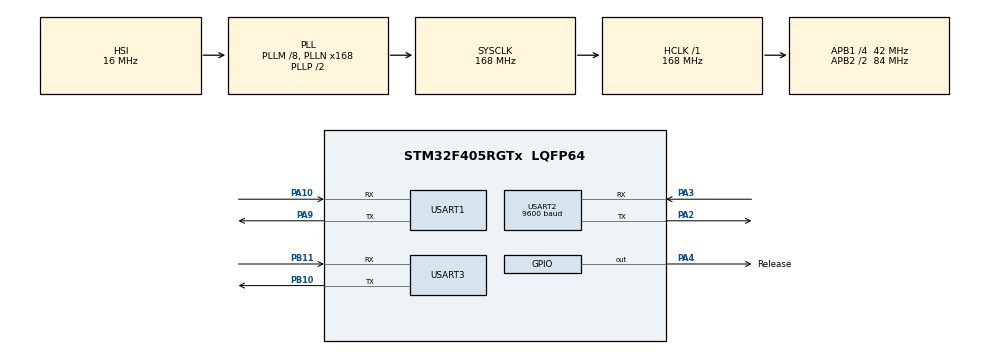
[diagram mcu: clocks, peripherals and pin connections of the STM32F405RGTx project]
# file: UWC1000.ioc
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FREERTOS.Tasks01=defaultTask,24,128,StartDefaultTask,Default,NULL,Dynamic,NULL,NULL;SensorTask,8,1024,StartSensorTask,Default,NULL,Dynamic,NULL,NULL;MavlinkTask,8,1024,StartMavlinkTask,Default,NULL,Dynamic,NULL,NULL;ReleaseTask,8,128,StartReleaseTask,Default,NULL,Dynamic,NULL,NULL
Mcu.Family=STM32F4
Mcu.Name=STM32F405RGTx
Mcu.Package=LQFP64
NVIC.PriorityGroup=NVIC_PRIORITYGROUP_4
NVIC.TIM6_DAC_IRQn=true\:15\:0\:false\:false\:true\:false\:false\:true\:true
NVIC.TimeBase=TIM6_DAC_IRQn
NVIC.TimeBaseIP=TIM6
NVIC.USART1_IRQn=true\:5\:0\:false\:false\:true\:true\:true\:true\:true
PA10.Mode=Asynchronous
PA10.Signal=USART1_RX
PA13.Mode=Serial_Wire
PA13.Signal=SYS_JTMS-SWDIO
PA14.Mode=Serial_Wire
PA14.Signal=SYS_JTCK-SWCLK
PA2.Mode=Asynchronous
PA2.Signal=USART2_TX
PA3.Mode=Asynchronous
PA3.Signal=USART2_RX
PA4.GPIO_Label=Release
PA4.Signal=GPIO_Output
PA9.Mode=Asynchronous
PA9.Signal=USART1_TX
PB10.Mode=Asynchronous
PB10.Signal=USART3_TX
PB11.Mode=Asynchronous
PB11.Signal=USART3_RX
PH0-OSC_IN.Mode=HSE-External-Clock-Source
PH0-OSC_IN.Signal=RCC_OSC_IN
PH1-OSC_OUT.Mode=HSE-External-Clock-Source
PH1-OSC_OUT.Signal=RCC_OSC_OUT
ProjectManager.HeapSize=0x200
ProjectManager.StackSize=0x400
ProjectManager.TargetToolchain=MDK-ARM V5.32
RCC.48MHZClocksFreq_Value=84000000
RCC.AHBFreq_Value=168000000
RCC.APB1CLKDivider=RCC_HCLK_DIV4
RCC.APB1Freq_Value=42000000
RCC.APB1TimFreq_Value=84000000
RCC.APB2CLKDivider=RCC_HCLK_DIV2
RCC.APB2Freq_Value=84000000
RCC.APB2TimFreq_Value=168000000
RCC.CortexFreq_Value=168000000
RCC.HCLKFreq_Value=168000000
RCC.HSE_VALUE=8000000
RCC.HSI_VALUE=16000000
RCC.LSE_VALUE=32768
RCC.PLLM=8
RCC.PLLN=168
RCC.SYSCLKFreq_VALUE=168000000
RCC.SYSCLKSource=RCC_SYSCLKSOURCE_PLLCLK
RCC.VCOOutputFreq_Value=336000000
USART1.VirtualMode=VM_ASYNC
USART2.BaudRate=9600
USART2.VirtualMode=VM_ASYNC
USART3.VirtualMode=VM_ASYNC
VP_FREERTOS_VS_CMSIS_V2.Mode=CMSIS_V2
VP_SYS_VS_tim6.Mode=TIM6
board=custom

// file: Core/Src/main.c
/* USER CODE BEGIN Header */
/**
  ******************************************************************************
  * @file           : main.c
  * @brief          : Main program body
  ******************************************************************************
  * @attention
  *
  * Copyright (c) 2026 STMicroelectronics.
  * All rights reserved.
  *
  * This software is licensed under terms that can be found in the LICENSE file
  * in the root directory of this software component.
  * If no LICENSE file comes with this software, it is provided AS-IS.
  *
  ******************************************************************************
  */
/* USER CODE END Header */
#include "main.h"
#include "cmsis_os.h"

/* USER CODE BEGIN Includes */
#include "mavlink_task.h"
#include "sensor_task.h"

/* USER CODE END Includes */

UART_HandleTypeDef huart1;
UART_HandleTypeDef huart2;
UART_HandleTypeDef huart3;

/* Definitions for defaultTask */
osThreadId_t defaultTaskHandle;
const osThreadAttr_t defaultTask_attributes = {
  .name = "defaultTask",
  .stack_size = 128 * 4,
  .priority = (osPriority_t) osPriorityNormal,
};
/* Definitions for SensorTask */
osThreadId_t SensorTaskHandle;
const osThreadAttr_t SensorTask_attributes = {
  .name = "SensorTask",
  .stack_size = 1024 * 4,
  .priority = (osPriority_t) osPriorityLow,
};
/* Definitions for MavlinkTask */
osThreadId_t MavlinkTaskHandle;
const osThreadAttr_t MavlinkTask_attributes = {
  .name = "MavlinkTask",
  .stack_size = 1024 * 4,
  .priority = (osPriority_t) osPriorityLow,
};
/* Definitions for ReleaseTask */
osThreadId_t ReleaseTaskHandle;
const osThreadAttr_t ReleaseTask_attributes = {
  .name = "ReleaseTask",
  .stack_size = 128 * 4,
  .priority = (osPriority_t) osPriorityLow,
};

void SystemClock_Config(void);
static void MX_GPIO_Init(void);
static void MX_USART1_UART_Init(void);
static void MX_USART2_UART_Init(void);
static void MX_USART3_UART_Init(void);
void StartDefaultTask(void *argument);
void StartSensorTask(void *argument);
void StartMavlinkTask(void *argument);
void StartReleaseTask(void *argument);

int main(void)
{

  /* MCU Configuration--------------------------------------------------------*/

  /* Reset of all peripherals, Initializes the Flash interface and the Systick. */
  HAL_Init();

  /* Configure the system clock */
  SystemClock_Config();

  /* Initialize all configured peripherals */
  MX_GPIO_Init();
  MX_USART1_UART_Init();
  MX_USART2_UART_Init();
  MX_USART3_UART_Init();

  /* Init scheduler */
  osKernelInitialize();

  /* Create the thread(s) */
  /* creation of defaultTask */
  defaultTaskHandle = osThreadNew(StartDefaultTask, NULL, &defaultTask_attributes);

  /* creation of SensorTask */
  SensorTaskHandle = osThreadNew(StartSensorTask, NULL, &SensorTask_attributes);

  /* creation of MavlinkTask */
  MavlinkTaskHandle = osThreadNew(StartMavlinkTask, NULL, &MavlinkTask_attributes);

  /* creation of ReleaseTask */
  ReleaseTaskHandle = osThreadNew(StartReleaseTask, NULL, &ReleaseTask_attributes);

  /* Start scheduler */
  osKernelStart();

  /* We should never get here as control is now taken by the scheduler */

  /* Infinite loop */
  while (1)
  {

  }
}

void SystemClock_Config(void)
{
  RCC_OscInitTypeDef RCC_OscInitStruct = {0};
  RCC_ClkInitTypeDef RCC_ClkInitStruct = {0};

  /** Configure the main internal regulator output voltage
  */
  __HAL_RCC_PWR_CLK_ENABLE();
  __HAL_PWR_VOLTAGESCALING_CONFIG(PWR_REGULATOR_VOLTAGE_SCALE1);

  /** Initializes the RCC Oscillators according to the specified parameters
  * in the RCC_OscInitTypeDef structure.
  */
  RCC_OscInitStruct.OscillatorType = RCC_OSCILLATORTYPE_HSI;
  RCC_OscInitStruct.HSIState = RCC_HSI_ON;
  RCC_OscInitStruct.HSICalibrationValue = RCC_HSICALIBRATION_DEFAULT;
  RCC_OscInitStruct.PLL.PLLState = RCC_PLL_ON;
  RCC_OscInitStruct.PLL.PLLSource = RCC_PLLSOURCE_HSI;
  RCC_OscInitStruct.PLL.PLLM = 8;
  RCC_OscInitStruct.PLL.PLLN = 168;
  RCC_OscInitStruct.PLL.PLLP = RCC_PLLP_DIV2;
  RCC_OscInitStruct.PLL.PLLQ = 4;
  if (HAL_RCC_OscConfig(&RCC_OscInitStruct) != HAL_OK)
  {
    Error_Handler();
  }

  /** Initializes the CPU, AHB and APB buses clocks
  */
  RCC_ClkInitStruct.ClockType = RCC_CLOCKTYPE_HCLK|RCC_CLOCKTYPE_SYSCLK
                              |RCC_CLOCKTYPE_PCLK1|RCC_CLOCKTYPE_PCLK2;
  RCC_ClkInitStruct.SYSCLKSource = RCC_SYSCLKSOURCE_PLLCLK;
  RCC_ClkInitStruct.AHBCLKDivider = RCC_SYSCLK_DIV1;
  RCC_ClkInitStruct.APB1CLKDivider = RCC_HCLK_DIV4;
  RCC_ClkInitStruct.APB2CLKDivider = RCC_HCLK_DIV2;

  if (HAL_RCC_ClockConfig(&RCC_ClkInitStruct, FLASH_LATENCY_5) != HAL_OK)
  {
    Error_Handler();
  }
}

static void MX_USART1_UART_Init(void)
{

  huart1.Instance = USART1;
  huart1.Init.BaudRate = 115200;
  huart1.Init.WordLength = UART_WORDLENGTH_8B;
  huart1.Init.StopBits = UART_STOPBITS_1;
  huart1.Init.Parity = UART_PARITY_NONE;
  huart1.Init.Mode = UART_MODE_TX_RX;
  huart1.Init.HwFlowCtl = UART_HWCONTROL_NONE;
  huart1.Init.OverSampling = UART_OVERSAMPLING_16;
  if (HAL_UART_Init(&huart1) != HAL_OK)
  {
    Error_Handler();
  }

}

static void MX_USART2_UART_Init(void)
{

  huart2.Instance = USART2;
  huart2.Init.BaudRate = 9600;
  huart2.Init.WordLength = UART_WORDLENGTH_8B;
  huart2.Init.StopBits = UART_STOPBITS_1;
  huart2.Init.Parity = UART_PARITY_NONE;
  huart2.Init.Mode = UART_MODE_TX_RX;
  huart2.Init.HwFlowCtl = UART_HWCONTROL_NONE;
  huart2.Init.OverSampling = UART_OVERSAMPLING_16;
  if (HAL_UART_Init(&huart2) != HAL_OK)
  {
    Error_Handler();
  }

}

static void MX_USART3_UART_Init(void)
{

  huart3.Instance = USART3;
  huart3.Init.BaudRate = 115200;
  huart3.Init.WordLength = UART_WORDLENGTH_8B;
  huart3.Init.StopBits = UART_STOPBITS_1;
  huart3.Init.Parity = UART_PARITY_NONE;
  huart3.Init.Mode = UART_MODE_TX_RX;
  huart3.Init.HwFlowCtl = UART_HWCONTROL_NONE;
  huart3.Init.OverSampling = UART_OVERSAMPLING_16;
  if (HAL_UART_Init(&huart3) != HAL_OK)
  {
    Error_Handler();
  }

}

static void MX_GPIO_Init(void)
{
  GPIO_InitTypeDef GPIO_InitStruct = {0};

  /* GPIO Ports Clock Enable */
  __HAL_RCC_GPIOH_CLK_ENABLE();
  __HAL_RCC_GPIOA_CLK_ENABLE();
  __HAL_RCC_GPIOB_CLK_ENABLE();

  /*Configure GPIO pin Output Level */
  HAL_GPIO_WritePin(Release_GPIO_Port, Release_Pin, GPIO_PIN_RESET);

  /*Configure GPIO pin : Release_Pin */
  GPIO_InitStruct.Pin = Release_Pin;
  GPIO_InitStruct.Mode = GPIO_MODE_OUTPUT_PP;
  GPIO_InitStruct.Pull = GPIO_NOPULL;
  GPIO_InitStruct.Speed = GPIO_SPEED_FREQ_LOW;
  HAL_GPIO_Init(Release_GPIO_Port, &GPIO_InitStruct);

}

void StartDefaultTask(void *argument)
{
  for(;;)
  {
    osDelay(1);
  }
}

void StartSensorTask(void *argument)
{
  /* USER CODE BEGIN StartSensorTask */
  SensorTask_Run();
  /* USER CODE END StartSensorTask */
}

void StartMavlinkTask(void *argument)
{
  /* USER CODE BEGIN StartMavlinkTask */
  MavlinkTask_Run();
  /* USER CODE END StartMavlinkTask */
}

void StartReleaseTask(void *argument)
{
  for(;;)
  {
    osDelay(1);
  }
}

void HAL_TIM_PeriodElapsedCallback(TIM_HandleTypeDef *htim)
{
  if (htim->Instance == TIM6)
  {
    HAL_IncTick();
  }
}

void Error_Handler(void)
{
  __disable_irq();
  while (1)
  {
  }
}
